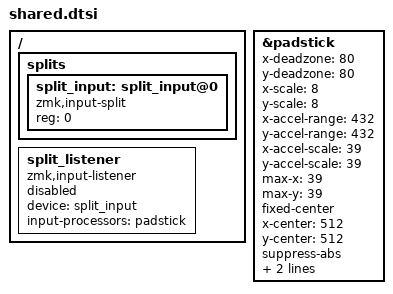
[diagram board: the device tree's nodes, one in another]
/*
 * Copyright (c) 2026 amgskobo
 * SPDX-License-Identifier: MIT
 *
 * What both halves share: the peripheral's pad reaches the central through a
 * ZMK input split, where a fixed-center PadStick turns it into a joystick.
 */

#include <zmk-input-padstick/input_processor_padstick.dtsi>
#include <zephyr/dt-bindings/input/input-event-codes.h>

#define TOUCH(delay, x, y)                                                                         \
    delay INPUT_EV_KEY INPUT_BTN_TOUCH 1 0 0 INPUT_EV_ABS INPUT_ABS_X (x) 0 0 INPUT_EV_ABS         \
        INPUT_ABS_Y (y) 1
#define POS(delay, x, y) delay INPUT_EV_ABS INPUT_ABS_X (x) 0 0 INPUT_EV_ABS INPUT_ABS_Y (y) 1
#define LIFT(delay) delay INPUT_EV_KEY INPUT_BTN_TOUCH 0 1

&padstick {
    x-deadzone = <80>;
    y-deadzone = <80>;
    x-scale = <8>;
    y-scale = <8>;
    x-accel-range = <432>;
    y-accel-range = <432>;
    x-accel-scale = <39>;
    y-accel-scale = <39>;
    max-x = <39>;
    max-y = <39>;
    fixed-center;
    x-center = <512>;
    y-center = <512>;
    suppress-abs;
    suppress-btn-touch;
    suppress-btn0;
};

/ {
    splits {
        #address-cells = <1>;
        #size-cells = <0>;

        split_input: split_input@0 {
            compatible = "zmk,input-split";
            reg = <0>;
        };
    };

    split_listener: split_listener {
        compatible = "zmk,input-listener";
        status = "disabled";
        device = <&split_input>;
        input-processors = <&padstick>;
    };
};
